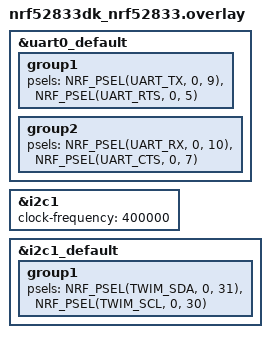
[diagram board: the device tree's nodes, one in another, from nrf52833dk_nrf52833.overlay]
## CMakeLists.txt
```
# SPDX-License-Identifier: Apache-2.0

cmake_minimum_required(VERSION 3.20.0)

find_package(Zephyr REQUIRED HINTS $ENV{ZEPHYR_BASE})
project(NONE)

FILE(GLOB app_sources src/*.c)
# NORDIC SDK APP START
target_sources(app PRIVATE ${app_sources})
# NORDIC SDK APP END
# SPDX-License-Identifier: Apache-2.0
set(FLASH_RUNNER nrfjprog CACHE STRING "" FORCE)
```

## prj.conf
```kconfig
CONFIG_NRFX_TWI0=y
CONFIG_LOG=y


CONFIG_CLOCK_CONTROL_NRF_K32SRC_RC=y
CONFIG_MAIN_STACK_SIZE=1024
CONFIG_NFCT_PINS_AS_GPIOS=y

CONFIG_PM=y
CONFIG_PM_DEVICE=y
CONFIG_PM_DEVICE_RUNTIME=y
```

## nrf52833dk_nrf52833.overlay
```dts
// To get started, press Ctrl+Space to bring up the completion menu and view the available nodes.

// You can also use the buttons in the sidebar to perform actions on nodes.
// Actions currently available include:

// * Enabling / disabling the node
// * Adding the bus to a bus
// * Removing the node
// * Connecting ADC channels

// For more help, browse the DeviceTree documentation at https://docs.zephyrproject.org/latest/guides/dts/index.html
// You can also visit the nRF DeviceTree extension documentation at https://docs.nordicsemi.com/bundle/nrf-connect-vscode/page/guides/ncs_configure_app.html#devicetree-support-in-the-extension

&uart0_default {
	group1 {
		psels = <NRF_PSEL(UART_TX, 0, 9)>, <NRF_PSEL(UART_RTS, 0, 5)>;
	};

	group2 {
		psels = <NRF_PSEL(UART_RX, 0, 10)>, <NRF_PSEL(UART_CTS, 0, 7)>;
	};
};

&i2c1 {
    status = "okay";
    clock-frequency = <400000>;
};

&i2c1_default {
    group1 {
        psels = <NRF_PSEL(TWIM_SDA, 0, 31)>, <NRF_PSEL(TWIM_SCL, 0, 30)>;
    };
};
```

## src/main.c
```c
/*
 * Copyright (c) 2012-2014 Wind River Systems, Inc.
 *
 * SPDX-License-Identifier: Apache-2.0
 */

#include <zephyr/kernel.h>
#include "io.h"
#include "i2c.h"
#include <zephyr/logging/log.h>
#include "ext_io.h"
#include "pinmap.h"
#include "nrfx_power.h"
#include "bat_manage.h"
#include <hal/nrf_power.h>

LOG_MODULE_REGISTER(main, LOG_LEVEL_DBG);

static int regout0_init(void)
{
    /* 若已为 3.3 V 则跳过 */
    if ((NRF_UICR->REGOUT0 & UICR_REGOUT0_VOUT_Msk) ==
         UICR_REGOUT0_VOUT_3V3)
        return 0;

    /* 解锁 NVMC 以写 UICR */
    NRF_NVMC->CONFIG = NVMC_CONFIG_WEN_Wen << NVMC_CONFIG_WEN_Pos;
    while (!NRF_NVMC->READY) { }

    NRF_UICR->REGOUT0 = (NRF_UICR->REGOUT0 &
                         ~UICR_REGOUT0_VOUT_Msk) |
                        UICR_REGOUT0_VOUT_3V3;

    while (!NRF_NVMC->READY) { }
    NRF_NVMC->CONFIG = NVMC_CONFIG_WEN_Ren << NVMC_CONFIG_WEN_Pos;

    /* 强制复位，让新电压生效 */
    NVIC_SystemReset();
    return 0; /* 不会执行到这里 */
}

int i = 0;
int main(void)
{
    regout0_init();

	LOG_DBG("Begin");
	// i2c_init();
	// io_init();

    bat_boost_enable(0);
    current_sample_power_enable(0);

    bat_charger_power_enable(0);
    bat_charger_enable(0);

    ao_en_enable(0);


    while (1)
    {
        // bat_vbat_adc_get();
        // k_msleep(100);
        // statu_led_set(0);
        // k_msleep(1000);
		// i++;
		// LOG_DBG("Hello World! %d", i);
        
        // statu_led_set(1);
        k_msleep(1000);
        
        // nrf_power_system_off(NRF_POWER);
    }

    return 0;
}
```

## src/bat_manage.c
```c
#include <zephyr/kernel.h>
#include "io.h"
#include "i2c.h"
#include <zephyr/logging/log.h>
#include "ext_io.h"
#include "pinmap.h"
#include "nrfx_power.h"
#include "bat_manage.h"


LOG_MODULE_REGISTER(bat, LOG_LEVEL_DBG);


int bat_manage_check(void)
{
    uint8_t val = i2c_read_bytes(BAT_MANAGE_IC_ADDR, BAT_INFO_ADDR);
    if (val == 0x08)
    {
        LOG_DBG("Battery management chip is online");
        return 1;
    }
    else
    {
        LOG_ERR("Battery management chip is offline");
    }
    return 0;
}

int is_bat_online(void)
{
    uint8_t val = i2c_read_bytes(BAT_MANAGE_IC_ADDR, BAT_REG1D_CHARGER_STATUS_2);
    if (val & 0x01)
    {
        LOG_DBG("Battery is online");
        return 1;
    }
    else
    {
        LOG_ERR("Battery is offline");
    }
    return 0;
}

int bat_manage_adc_init(void)
{
    uint8_t val = 0x00;
    i2c_write_bytes(BAT_MANAGE_IC_ADDR, 0x01, val);
    return 0;
}

int bat_adc_status_get(void)
{
    uint8_t val = i2c_read_bytes(BAT_MANAGE_IC_ADDR, BAT_ADC_DISABLE_0);
    LOG_DBG("ADC status 0: %02x", val);
    val = i2c_read_bytes(BAT_MANAGE_IC_ADDR, BAT_ADC_DISABLE_1);
    LOG_DBG("ADC status 1: %02x", val);
    val = i2c_read_bytes(BAT_MANAGE_IC_ADDR, BAT_REG2E_ADC_CONTROL);
    LOG_DBG("ADC control 0x2E: %02x", val);

    i2c_write_bytes(BAT_MANAGE_IC_ADDR, BAT_REG2E_ADC_CONTROL, 0xB0);

    return 0;
}

int bat_current_get(void)
{
    uint8_t val[2] = {0};
    i2c_read_array(BAT_MANAGE_IC_ADDR, BAT_IBAT_ADC, val, 2);
    int16_t current = (val[0] << 8) | val[1];
    LOG_DBG("Battery current: %d", current);
    return current;
}

int bat_charger_status_get(void)
{
    uint8_t val = i2c_read_bytes(BAT_MANAGE_IC_ADDR, BAT_REG1C_CHARGER_STATUS_1);
    LOG_DBG("Charger status: %02x", val);
    return val;
}

int bat_temperature_get(void)
{
    uint8_t val[2] = {0};
    i2c_read_array(BAT_MANAGE_IC_ADDR, BAT_TEMP_ADC, val, 2);
    uint16_t temperature_val = (val[0] << 8) | val[1];
    int temperature = temperature_val  * 0.0976563;
    LOG_DBG("Battery temperature: %d", temperature);
    return temperature;
}

int bat_manage_ic_temp_get(void)
{
    uint8_t val[2] = {0};
    i2c_read_array(BAT_MANAGE_IC_ADDR, BAT_IC_TEMP, val, 2);
    uint16_t temperature_val = (val[0] << 8) | val[1];
    int temperature = -40 + (temperature_val * 0.5);
    LOG_DBG("Battery management chip temperature: %d ", temperature);
    return temperature;
}

int bat_disable_ico(void)
{
    uint8_t val = i2c_read_bytes(BAT_MANAGE_IC_ADDR, BAT_REG0F_CHARGER_CONTROL_0);
    val &= ~((1 << 4) | (1 << 1)); // Clear EN_ICO and FORCE_ICO
    i2c_write_bytes(BAT_MANAGE_IC_ADDR, BAT_REG0F_CHARGER_CONTROL_0, val);
    val = i2c_read_bytes(BAT_MANAGE_IC_ADDR, BAT_REG0F_CHARGER_CONTROL_0);
    LOG_DBG("Charger control register 0x0F: %02x", val);
    return 0;
}


int bat_charger_current_limit_set(uint16_t limit)
{
    uint8_t val[2] = {0};
    if (limit > 5000)
    {
        limit = 5000;
    }

    uint16_t limit_val = limit / 10;
    val[0] = limit_val & 0xFF;
    val[1] = (limit_val >> 8) & 0xFF;

    LOG_DBG("Charger current limit: %02x %02x", val[0], val[1]);

    bat_disable_ico();

    i2c_write_array(BAT_MANAGE_IC_ADDR, BAT_REG03_CURRENT_LIMIT, val, 2);

    uint8_t val_r[2] = {0};
    i2c_read_array(BAT_MANAGE_IC_ADDR, BAT_REG03_CURRENT_LIMIT, val_r, 2);
    uint16_t current_limit = (val_r[0] | (val_r[1] << 8)) * 10;
    LOG_DBG("Charger current limit set to: %d", current_limit);
    return current_limit;

}

int bat_charger_control_set(void)
{
    uint8_t val = i2c_read_bytes(BAT_MANAGE_IC_ADDR, BAT_REG0F_CHARGER_CONTROL_0);
    LOG_DBG("Charger control register: %02x", val);
}

int bat_charger_enable_set(uint8_t enable)
{
    uint8_t val = i2c_read_bytes(BAT_MANAGE_IC_ADDR, BAT_REG0F_CHARGER_CONTROL_0);
    if (enable)
    {
        val |= 0x20;
    }
    else
    {
        val &= ~0x20;
    }
    i2c_write_bytes(BAT_MANAGE_IC_ADDR, BAT_REG0F_CHARGER_CONTROL_0, val);
    return 0;
}

int bat_reg10_charger_control_1_get(void)
{
    uint8_t val = i2c_read_bytes(BAT_MANAGE_IC_ADDR, BAT_REG10_CHARGER_CONTROL_1);
    LOG_DBG("Charger control register 1: %02x", val);
    return val;
}

int bat_reg10_disable_watchdog(void)
{
    uint8_t val = i2c_read_bytes(BAT_MANAGE_IC_ADDR, BAT_REG10_CHARGER_CONTROL_1);
    val &= ~0x07;
    i2c_write_bytes(BAT_MANAGE_IC_ADDR, BAT_REG10_CHARGER_CONTROL_1, val);
    return 0;
}


int bat_input_current_limit_set(uint16_t limit)
{
    uint8_t val[2] = {0};
    if (limit > 3300)
    {
        limit = 3300;
    }

    uint16_t limit_val = (limit - 100) / 10;
    val[0] = limit_val & 0xFF;
    val[1] = (limit_val >> 8) & 0xFF;
    i2c_write_array(BAT_MANAGE_IC_ADDR, BAT_INPUT_CURRENT_LIMIT, val, 2);

    uint8_t val_r[2] = {0};
    i2c_read_array(BAT_MANAGE_IC_ADDR, BAT_INPUT_CURRENT_LIMIT, val_r, 2);
    uint16_t current_limit = (val_r[0] | (val_r[1] << 8)) * 10;
    LOG_DBG("Input current limit set to: %d", current_limit);
    return current_limit;

}

int bat_vbat_adc_get(void)
{
    uint8_t val[2] = {0};
    i2c_read_array(BAT_MANAGE_IC_ADDR, BAT_REG3B_VBAT_ADC, val, 2);
    uint16_t vbat_val = (val[0] << 8) | val[1];
    LOG_DBG("Battery voltage: %d mV", vbat_val);
    return vbat_val;
}
```

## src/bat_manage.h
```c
#ifndef BAT_MANAGE_H
#define BAT_MANAGE_H

#include <zephyr/kernel.h>
#include "io.h"
#include "i2c.h"
#include <zephyr/logging/log.h>
#include "ext_io.h"
#include "pinmap.h"
#include "nrfx_power.h"

#define BAT_MANAGE_IC_ADDR 0x6B
#define BAT_INFO_ADDR 0x48
#define BAT_REG1D_CHARGER_STATUS_2 0x1D
#define BAT_IBAT_ADC 0x33
#define BAT_ADC_DISABLE_0 0x2F
#define BAT_ADC_DISABLE_1 0x30
#define BAT_REG1C_CHARGER_STATUS_1 0x1C
#define BAT_REG2E_ADC_CONTROL 0x2E
#define BAT_IC_TEMP 0x41
#define BAT_TEMP_ADC 0x3F
#define BAT_REG03_CURRENT_LIMIT 0x03
#define BAT_REG0F_CHARGER_CONTROL_0 0x0F
#define BAT_INPUT_CURRENT_LIMIT 0x06
#define BAT_REG10_CHARGER_CONTROL_1 0x10
#define BAT_REG3B_VBAT_ADC 0x3B



int bat_manage_check(void);
int is_bat_online(void);
int bat_manage_adc_init(void);
int bat_adc_status_get(void);
int bat_current_get(void);
int bat_charger_status_get(void);
int bat_temperature_get(void);
int bat_manage_ic_temp_get(void);
int bat_disable_ico(void);
int bat_charger_current_limit_set(uint16_t limit);
int bat_charger_control_set(void);
int bat_charger_enable_set(uint8_t enable);
int bat_reg10_charger_control_1_get(void);
int bat_reg10_disable_watchdog(void);
int bat_input_current_limit_set(uint16_t limit);
int bat_vbat_adc_get(void);

#endif // BAT_MANAGE_H
```

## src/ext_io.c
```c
#include <zephyr/kernel.h>
#include <nrfx_twi.h>
#include <hal/nrf_gpio.h>
#include <zephyr/logging/log.h>
#include "i2c.h"
#include "zephyr/logging/log.h"
#include "ext_io.h"
#include "pinmap.h"


#define EXT_IC_ADDR               0x43  // 7-bit I2C 地址（ADDR 引脚接 GND）

#define REG_DEVICE_ID_CTRL        0x01  // 设备 ID 与控制
#define REG_IO_DIRECTION          0x03  // 引脚方向设置
#define REG_OUTPUT_STATE          0x05  // 输出状态控制
#define REG_PULL_ENABLE           0x0B  // 上拉使能
#define REG_OUTPUT_HIGH_Z         0x07  // 高阻态设置（可选）
#define REG_PULL_DOWN_UP         0x0D  // 上拉/下拉设置（可选）
#define REG_INPUT_STATUS         0x0F  // 输入状态读取

uint8_t ext_io_output_global_val = 0; 


LOG_MODULE_REGISTER(ext_io, LOG_LEVEL_DBG);

void ext_io_sw_reset(void)
{
    uint8_t val = 0x01;
    i2c_write_bytes(EXT_IC_ADDR, REG_DEVICE_ID_CTRL, val);
    k_msleep(10); // 等待 10ms
    val = 0x00;
    i2c_write_bytes(EXT_IC_ADDR, REG_DEVICE_ID_CTRL, val);
    k_msleep(10); // 等待 10ms
    LOG_DBG("External IO reset");
}

uint8_t ext_io_get_io_direction(void)
{
    uint8_t val = i2c_read_bytes(EXT_IC_ADDR, REG_IO_DIRECTION);
    char dir[16] = {0};
    for(uint8_t i = 0; i < 8; i++)
    {
        if(val & (1 << i))
        {
            snprintf(dir + i, 2, "O");  
        }
        else
        {
            snprintf(dir + i, 2, "I");
        }
    }
    LOG_DBG("IO direction: %s", dir);
    return val;
}

void ext_io_set_io_set_all_output(void)
{
    uint8_t val = 0xFF; // 全部设置为输出
    i2c_write_bytes(EXT_IC_ADDR, REG_IO_DIRECTION, val);
    LOG_DBG("Set all IO to output");
}

void ext_io_set_io_set_all_input(void)
{
    uint8_t val = 0x00; // 全部设置为输入
    i2c_write_bytes(EXT_IC_ADDR, REG_IO_DIRECTION, val);
    LOG_DBG("Set all IO to input");
}

void ext_io_set_io_direction(uint8_t io_num, enum ext_io_dir_e dir)
{
    uint8_t val = ext_io_get_io_direction();
    uint8_t new_val = 0;
    
    if(io_num > 7)
    {
        LOG_ERR("Invalid IO number: %d", io_num);
        return;
    }

    if(dir == EXT_IO_DIR_INPUT) // 设置为输入
    {
        val &= ~(1 << io_num);
    }
    else // 设置为输出
    {
        val |= (1 << io_num);
    }
    i2c_write_bytes(EXT_IC_ADDR, REG_IO_DIRECTION, val);
    new_val = ext_io_get_io_direction();

    if(new_val != val)
    {
        LOG_ERR("Failed to set IO direction: %d", io_num);
    }
    else
    {
        LOG_DBG("Set IO %d direction to %s", io_num, dir ? "output" : "input");
    }
}

uint8_t ext_io_get_output_state(void)
{

    return ext_io_output_global_val;

    uint8_t val = i2c_read_bytes(EXT_IC_ADDR, REG_OUTPUT_STATE);
    char state[16] = {0};
    for(uint8_t i = 0; i < 8; i++)
    {
        if(val & (1 << i))
        {
            snprintf(state + i, 2, "H");  

        }
        else
        {
            snprintf(state + i, 2, "L");

        }
    }   
    // LOG_DBG("Output state: %s", state);
    return val;
}

void ext_io_set_output_state(uint8_t io_num, uint8_t state)
{
    uint8_t val = ext_io_get_output_state();
    uint8_t new_val = 0;
    
    if(io_num > 7)
    {
        LOG_ERR("Invalid IO number: %d", io_num);
        return;
    }
    
    if(state) // 设置为高电平
    {
        val |= (1 << io_num);
    }
    else // 设置为低电平
    {
        val &= ~(1 << io_num);
    }
    ext_io_output_global_val = val;
    i2c_write_bytes(EXT_IC_ADDR, REG_OUTPUT_STATE, ext_io_output_global_val);
    new_val = ext_io_get_output_state();

    if(new_val != val)
    {
        LOG_ERR("Failed to set output state: %d", io_num);
    }
    else
    {
        LOG_DBG("Set output %d state to %s", io_num, state ? "high" : "low");
    }
}

uint8_t ext_io_get_output_high_z(void)
{
    uint8_t val = i2c_read_bytes(EXT_IC_ADDR, REG_OUTPUT_HIGH_Z);
    char state[16] = {0};
    for(uint8_t i = 0; i < 8; i++)
    {
        if(val & (1 << i))
        {
            snprintf(state + i, 2, "Z");  
        }
        else
        {
            snprintf(state + i, 2, "P");
        }
    }   
    LOG_DBG("Output high Z: %s", state);
    return val;
}

void ext_io_set_output_high_z(uint8_t io_num, uint8_t state)
{
    uint8_t val = ext_io_get_output_high_z();
    uint8_t new_val = 0;
    
    if(io_num > 7)
    {
        LOG_ERR("Invalid IO number: %d", io_num);
        return;
    }

    if(state) // 设置为高阻态
    {
        val |= (1 << io_num);
    }
    else // 设置为推挽输出
    {
        val &= ~(1 << io_num);
    }
    i2c_write_bytes(EXT_IC_ADDR, REG_OUTPUT_HIGH_Z, val);
    new_val = ext_io_get_output_high_z();

    if(new_val != val)
    {
        LOG_ERR("Failed to set output high Z: %d", io_num);
    }
    else
    {
        LOG_DBG("Set output %d high Z to %s", io_num, state ? "high Z" : "push-pull");
    }
}

uint8_t ext_io_get_pull_enable(void)
{
    uint8_t val = i2c_read_bytes(EXT_IC_ADDR, REG_PULL_ENABLE);
    char state[16] = {0};
    for(uint8_t i = 0; i < 8; i++)
    {
        if(val & (1 << i))
        {
            snprintf(state + i, 2, "P");  
        }
        else
        {
            snprintf(state + i, 2, "N");
        }
    }   
    LOG_DBG("Pull enable: %s", state);
    return val;
}

uint8_t ext_io_get_pull_Down_up(void)
{
    uint8_t val = i2c_read_bytes(EXT_IC_ADDR, REG_PULL_DOWN_UP);
    char state[16] = {0};
    for(uint8_t i = 0; i < 8; i++)
    {
        if(val & (1 << i))
        {
            snprintf(state + i, 2, "U");  
        }
        else
        {
            snprintf(state + i, 2, "D");
        }
    }   
    LOG_DBG("Pull up/down: %s", state);
    return val;
}

uint8_t ext_io_get_input_state(void)
{
    uint8_t val = i2c_read_bytes(EXT_IC_ADDR, REG_INPUT_STATUS);
    char state[16] = {0};
    for(uint8_t i = 0; i < 8; i++)
    {
        if(val & (1 << i))
        {
            snprintf(state + i, 2, "H");  
        }
        else
        {
            snprintf(state + i, 2, "L");
        }
    }   
    LOG_DBG("Input state: %s", state);
    return val;
}

uint8_t ext_io_get_channel_state(uint8_t io_num)
{
    uint8_t val = ext_io_get_input_state();
    
    if(io_num > 7)
    {
        LOG_ERR("Invalid IO number: %d", io_num);
        return 0;
    }

    if(val & (1 << io_num))
    {
        return 1; // 高电平
    }
    else
    {
        return 0; // 低电平
    }
}

uint8_t ext_io_set_pull_enable(uint8_t io_num, uint8_t enable)
{
    uint8_t val = ext_io_get_pull_enable();
    uint8_t new_val = 0;
    
    if(io_num > 7)
    {
        LOG_ERR("Invalid IO number: %d", io_num);
        return 0;
    }

    if(enable) // 设置为使能
    {
        val |= (1 << io_num);
    }
    else // 设置为不使能
    {
        val &= ~(1 << io_num);
    }
    i2c_write_bytes(EXT_IC_ADDR, REG_PULL_ENABLE, val);
    new_val = ext_io_get_pull_enable();

    if(new_val != val)
    {
        LOG_ERR("Failed to set pull enable: %d", io_num);
        return 0;
    }
    else
    {
        LOG_DBG("Set pull enable %d to %s", io_num, enable ? "enable" : "disable");
        return 1;
    }
}

uint8_t ext_io_set_pull_Down_up(uint8_t io_num, uint8_t pull)
{
    uint8_t val = ext_io_get_pull_Down_up();
    uint8_t new_val = 0;
    
    if(io_num > 7)
    {
        LOG_ERR("Invalid IO number: %d", io_num);
        return 0;
    }

    if(pull) // 设置为上拉
    {
        val |= (1 << io_num);
    }
    else // 设置为下拉
    {
        val &= ~(1 << io_num);
    }
    i2c_write_bytes(EXT_IC_ADDR, REG_PULL_DOWN_UP, val);
    new_val = ext_io_get_pull_Down_up();

    if(new_val != val)
    {
        LOG_ERR("Failed to set pull up/down: %d", io_num);
        return 0;
    }
    else
    {
        LOG_DBG("Set pull up/down %d to %s", io_num, pull ? "pull up" : "pull down");
        return 1;
    }
}



void ext_ic_check(void)
{
    uint8_t reg_val = i2c_read_bytes(EXT_IC_ADDR, 0x01);

    uint8_t mf_id     = (reg_val >> 5) & 0x07;  // Bit 7~5
    uint8_t fw_rev    = (reg_val >> 2) & 0x07;  // Bit 4~2
    uint8_t rst_int   = (reg_val >> 1) & 0x01;  // Bit 1
    uint8_t sw_rst    = (reg_val >> 0) & 0x01;  // Bit 0

    LOG_DBG("Manufacturer ID: 0x%X", mf_id);   // 应为 0b101 = 0x5
    LOG_DBG("Firmware Rev:   0x%X", fw_rev);
    LOG_DBG("Reset Flag:     %d", rst_int);
    LOG_DBG("SW Reset Flag:  %d", sw_rst);
}

void statu_led_set(uint8_t status)
{
    if(!status)
    {
        ext_io_set_output_state(LED_EXT_PIN, 1); // 设置为高电平
    }
    else
    {
        ext_io_set_output_state(LED_EXT_PIN, 0); // 设置为低电平
    }
}

uint8_t is_key_on(void)
{
    uint8_t key_state = !ext_io_get_channel_state(KEY_EXT_PIN);
    if(key_state == 1)
    {
        LOG_DBG("Key is pressed");
        return 1;
    }
    else
    {
        LOG_DBG("Key is not pressed");
        return 0;
    }
}

uint8_t is_usb_on(void)
{
    uint8_t usb_state = ext_io_get_channel_state(USB_EXT_PIN);
    if(usb_state == 1)
    {
        LOG_DBG("USB is connected");
        return 1;
    }
    else
    {
        LOG_DBG("USB is not connected");
        return 0;
    }
}


uint8_t ext_io_init(void)
{
    ext_io_sw_reset();

    uint8_t dev_id = i2c_read_bytes(EXT_IC_ADDR, REG_DEVICE_ID_CTRL);

    if (((dev_id >> 5) & 0x07) != 0x05) {
        LOG_ERR("Device not recognized. MF_ID = 0x%X", (dev_id >> 5) & 0x07);
        return false;
    }
    else {
        LOG_DBG("Device recognized. MF_ID = 0x%X", (dev_id >> 5) & 0x07);
    }


    ext_io_set_io_direction(LED_EXT_PIN, EXT_IO_DIR_OUTPUT);
    ext_io_set_io_direction(USB_EXT_PIN, EXT_IO_DIR_INPUT);
    ext_io_set_io_direction(KEY_EXT_PIN, EXT_IO_DIR_INPUT);
    ext_io_set_io_direction(LED_B1_EXT_PIN, EXT_IO_DIR_OUTPUT);
    ext_io_set_io_direction(LED_B2_EXT_PIN, EXT_IO_DIR_OUTPUT);
    ext_io_set_io_direction(LED_B3_EXT_PIN, EXT_IO_DIR_OUTPUT);
    ext_io_set_io_direction(BST_OD_OFF_EXT_PIN, EXT_IO_DIR_OUTPUT);
    ext_io_set_io_direction(PD_OD_OFF_EXT_PIN, EXT_IO_DIR_OUTPUT);

    ext_io_set_pull_enable(LED_EXT_PIN, 0);
    ext_io_set_pull_enable(LED_B1_EXT_PIN, 0);
    ext_io_set_pull_enable(LED_B2_EXT_PIN, 0);
    ext_io_set_pull_enable(LED_B3_EXT_PIN, 0);
    ext_io_set_pull_enable(USB_EXT_PIN, 1);  
    ext_io_set_pull_enable(KEY_EXT_PIN, 1);


    ext_io_set_pull_Down_up(USB_EXT_PIN, 0);    // 设置为下拉
    ext_io_set_pull_Down_up(KEY_EXT_PIN, 1);    // 设置为上拉

    ext_io_set_output_high_z(LED_EXT_PIN, 0); // 设置为推挽输出
    ext_io_set_output_high_z(LED_B1_EXT_PIN, 0); // 设置为推挽输出
    ext_io_set_output_high_z(LED_B2_EXT_PIN, 0); // 设置为推挽输出
    ext_io_set_output_high_z(LED_B3_EXT_PIN, 0); // 设置为推挽输出
    ext_io_set_output_high_z(BST_OD_OFF_EXT_PIN, 0); // 设置为推挽输出
    ext_io_set_output_high_z(PD_OD_OFF_EXT_PIN, 0); // 设置为推挽输出


    ext_io_set_output_state(LED_EXT_PIN, 1); 
    ext_io_set_output_state(LED_B1_EXT_PIN, 1); 
    ext_io_set_output_state(LED_B2_EXT_PIN, 1); 
    ext_io_set_output_state(LED_B3_EXT_PIN, 1);
    ext_io_set_output_state(BST_OD_OFF_EXT_PIN, 0); 
    ext_io_set_output_state(PD_OD_OFF_EXT_PIN, 0); 



    LOG_DBG("External IO initialized finished");

    return true;
}
```

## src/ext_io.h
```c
#ifndef EXT_IO_H
#define EXT_IO_H

#include <stdint.h>



enum ext_io_dir_e{
    EXT_IO_DIR_INPUT = 0,
    EXT_IO_DIR_OUTPUT = 1,
};

// ========== User-defined IO Pin Macros ==========
// Define external IO pin mapping in your project-specific pinmap.h
// Example:
//   #define LED_EXT_PIN            3
//   #define KEY_EXT_PIN            1
//   #define USB_EXT_PIN            2
//   #define LED_B1_EXT_PIN         4
//   #define LED_B2_EXT_PIN         5
//   #define LED_B3_EXT_PIN         6
//   #define BST_OD_OFF_EXT_PIN     7
//   #define PD_OD_OFF_EXT_PIN      0




// ========== Initialization and Status ==========

/**
 * @brief Initialize FXL6408 IO expander
 * @return 1 if successful, 0 if failed
 */
uint8_t ext_io_init(void);

/**
 * @brief Read and log manufacturer ID, firmware version and reset flags
 */
void ext_ic_check(void);


// ========== IO Direction Configuration ==========

/**
 * @brief Read current IO direction register
 * @return 8-bit direction register value
 */
uint8_t ext_io_get_io_direction(void);

/**
 * @brief Set all IOs as output
 */
void ext_io_set_io_set_all_output(void);

/**
 * @brief Set all IOs as input
 */
void ext_io_set_io_set_all_input(void);

/**
 * @brief Set direction for a single IO pin
 * @param io_num IO pin number (0–7)
 * @param dir Direction (input or output)
 */
void ext_io_set_io_direction(uint8_t io_num, enum ext_io_dir_e dir);


// ========== Output Control ==========

/**
 * @brief Read current output state
 * @return 8-bit output register value
 */
uint8_t ext_io_get_output_state(void);

/**
 * @brief Set output value of a single IO pin
 * @param io_num IO pin number (0–7)
 * @param state 1 = High, 0 = Low
 */
void ext_io_set_output_state(uint8_t io_num, uint8_t state);

/**
 * @brief Set output value for multiple pins using mask
 * @param mask Bit mask specifying which pins to modify
 * @param value Desired output values for masked pins
 */
void ext_io_set_output_masked(uint8_t mask, uint8_t value);


// ========== Output Mode: Push-Pull / High-Z ==========

/**
 * @brief Read High-Z state register
 * @return 8-bit value, 1 = High-Z, 0 = Push-pull
 */
uint8_t ext_io_get_output_high_z(void);

/**
 * @brief Configure High-Z or Push-Pull mode for a pin
 * @param io_num IO pin number (0–7)
 * @param state 1 = High-Z (open-drain), 0 = Push-pull
 */
void ext_io_set_output_high_z(uint8_t io_num, uint8_t state);


// ========== Pull-up / Pull-down Configuration ==========

/**
 * @brief Read pull-enable register
 * @return 8-bit value, 1 = Pull enabled, 0 = Disabled
 */
uint8_t ext_io_get_pull_enable(void);

/**
 * @brief Enable or disable internal pull resistor for a pin
 * @param io_num IO pin number (0–7)
 * @param enable 1 = Enable pull, 0 = Disable
 * @return 1 if successful, 0 if failed
 */
uint8_t ext_io_set_pull_enable(uint8_t io_num, uint8_t enable);

/**
 * @brief Read pull-up/down configuration
 * @return 8-bit value, 1 = Pull-up, 0 = Pull-down
 */
uint8_t ext_io_get_pull_Down_up(void);

/**
 * @brief Configure pull direction for a pin
 * @param io_num IO pin number (0–7)
 * @param pull 1 = Pull-up, 0 = Pull-down
 * @return 1 if successful, 0 if failed
 */
uint8_t ext_io_set_pull_Down_up(uint8_t io_num, uint8_t pull);


// ========== Input State ==========

/**
 * @brief Read all input states
 * @return 8-bit input level of all pins
 */
uint8_t ext_io_get_input_state(void);

/**
 * @brief Read input state of a single IO pin
 * @param io_num IO pin number (0–7)
 * @return 1 = High, 0 = Low
 */
uint8_t ext_io_get_channel_state(uint8_t io_num);


// ========== Application-level API ==========

/**
 * @brief Set status LED on or off
 * @param status 1 = On, 0 = Off
 */
void statu_led_set(uint8_t status);

/**
 * @brief Check if key input is active (pressed)
 * @return 1 = Pressed, 0 = Not pressed
 */
uint8_t is_key_on(void);

/**
 * @brief Check if USB is connected
 * @return 1 = Connected, 0 = Not connected
 */
uint8_t is_usb_on(void);


#endif // EXT_IO_H
```

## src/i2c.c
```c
#include <zephyr/kernel.h>
#include <nrfx_twi.h>
#include <hal/nrf_gpio.h>
#include <zephyr/logging/log.h>
#include "pinmap.h"
#include "i2c_zephyr.h"

LOG_MODULE_REGISTER(iic, LOG_LEVEL_DBG);

static const nrfx_twi_t twi = NRFX_TWI_INSTANCE(0);

void twi_handler(nrfx_twi_evt_t const * p_event, void * p_context) 
{
	switch (p_event->type) {
		case NRFX_TWI_EVT_DONE:
			/* Transfer completed */
			break;
		case NRFX_TWI_EVT_ADDRESS_NACK:
			/* NACK received after sending the address */
			break;
		case NRFX_TWI_EVT_DATA_NACK:
			/* NACK received after sending a data byte */
			break;
		default:
			break;
	}
}

void i2c_init(void)
{
	int err_code;
    nrfx_twi_config_t config = NRFX_TWI_DEFAULT_CONFIG(I2C_SCL_PIN, I2C_SDA_PIN);
	config.frequency = NRF_TWI_FREQ_400K;
    err_code = nrfx_twi_init(&twi, &config, twi_handler, NULL);
	if (err_code != NRFX_SUCCESS) {
		LOG_ERR("TWI initialization failed: %d", err_code);
		return;
	}
    IRQ_DIRECT_CONNECT(NRFX_IRQ_NUMBER_GET(NRF_TWI_INST_GET(0)), IRQ_PRIO_LOWEST,
                       NRFX_TWI_INST_HANDLER_GET(0), 0);
    nrfx_twi_enable(&twi);
}
uint8_t buffer[2] = {0};
uint8_t i2c_write_bytes(uint8_t ic_addr, uint8_t addr, uint8_t data) 
{
	z_i2c_write(ic_addr, addr, &data, 1);
	return 0;

	buffer[0] = addr;
	buffer[1] = data;
	nrfx_twi_xfer_desc_t xfer_desc = {
		.type = NRFX_TWI_XFER_TX,
		.address = ic_addr,
		.primary_length = sizeof(buffer),
		.p_primary_buf = buffer,
	};

	while(nrfx_twi_is_busy(&twi)){};
	nrfx_twi_xfer(&twi, &xfer_desc, 0);
	return 0;
}

uint8_t i2c_write_array(uint8_t ic_addr, uint8_t addr, uint8_t *data, uint8_t len) 
{
	uint8_t buffer[len + 1];
	buffer[0] = addr;
	for (int i = 0; i < len; i++) {
		buffer[i + 1] = data[i];
	}
	nrfx_twi_xfer_desc_t xfer_desc = {
		.type = NRFX_TWI_XFER_TXTX,
		.address = ic_addr,
		.primary_length = sizeof(buffer),
		.p_primary_buf = buffer,
	};

	while(nrfx_twi_is_busy(&twi)){};
	nrfx_twi_xfer(&twi, &xfer_desc, 0);
	return 0;
}


uint8_t i2c_read_bytes(uint8_t ic_addr, uint8_t addr) 
{
	uint8_t addr_buffer[1] = {addr};
	uint8_t data_buffer[1];

	z_i2c_read(ic_addr, addr, data_buffer, 1);
	return data_buffer[0];

	nrfx_twi_xfer_desc_t xfer_desc = {
		.type = NRFX_TWI_XFER_TXRX,
		.address = ic_addr,
		.primary_length = sizeof(addr_buffer),
		.p_primary_buf = addr_buffer,
		.secondary_length = sizeof(data_buffer),
		.p_secondary_buf = data_buffer,
	};

	
	nrfx_twi_xfer(&twi, &xfer_desc, 0);
	while(nrfx_twi_is_busy(&twi)){};
	return data_buffer[0];
}

uint8_t i2c_read_data_buffer[20] = {0};
uint8_t i2c_read_array(uint8_t ic_addr, uint8_t addr, uint8_t *data, uint8_t len) 
{
	uint8_t addr_buffer[1] = {addr};
	for (int i = 0; i < len; i++) {
		i2c_read_data_buffer[i] = 0;
	}

	nrfx_twi_xfer_desc_t xfer_desc = {
		.type = NRFX_TWI_XFER_TXRX,
		.address = ic_addr,
		.primary_length = sizeof(addr_buffer),
		.p_primary_buf = addr_buffer,
		.secondary_length = len,
		.p_secondary_buf = i2c_read_data_buffer,
	};

	
	nrfx_twi_xfer(&twi, &xfer_desc, 0);
	while(nrfx_twi_is_busy(&twi)){};
	for (int i = 0; i < len; i++) {
		data[i] = i2c_read_data_buffer[i];
	}
	return 0;
}
```

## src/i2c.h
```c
#ifndef I2C_H
#define I2C_H

#include <stdint.h>

void i2c_init(void);
uint8_t i2c_write_bytes(uint8_t ic_addr, uint8_t addr, uint8_t data);
uint8_t i2c_write_array(uint8_t ic_addr, uint8_t addr, uint8_t *data, uint8_t len);
uint8_t i2c_read_bytes(uint8_t ic_addr, uint8_t addr);
uint8_t i2c_read_array(uint8_t ic_addr, uint8_t addr, uint8_t *data, uint8_t len);

#endif // I2C_H
```

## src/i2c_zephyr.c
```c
#include <zephyr/kernel.h>
#include <zephyr/device.h>
#include <zephyr/devicetree.h>
#include <zephyr/logging/log.h>
#include <zephyr/drivers/i2c.h>


LOG_MODULE_REGISTER(i2c_zephyr, LOG_LEVEL_DBG);
const struct device *i2c_dev = DEVICE_DT_GET(DT_NODELABEL(i2c1));

void z_i2c_write(uint8_t ic_addr, uint8_t addr, uint8_t *data, uint8_t len)
{
	struct i2c_msg msgs[2];
	msgs[0].buf = &addr;
	msgs[0].len = 1;
	msgs[0].flags = I2C_MSG_WRITE;
	msgs[1].buf = data;
	msgs[1].len = len;
	msgs[1].flags = I2C_MSG_WRITE | I2C_MSG_STOP;

	i2c_transfer(i2c_dev, msgs, 2, ic_addr);
}

void z_i2c_read(uint8_t ic_addr, uint8_t addr, uint8_t *data, uint8_t len)
{
	struct i2c_msg msgs[2];
	msgs[0].buf = &addr;
	msgs[0].len = 1;
	msgs[0].flags = I2C_MSG_WRITE | I2C_MSG_STOP;
	msgs[1].buf = data;
	msgs[1].len = len;
	msgs[1].flags = I2C_MSG_READ | I2C_MSG_STOP;

	i2c_transfer(i2c_dev, msgs, 2, ic_addr);
}

void z_i2c_init(void)
{
	if(!device_is_ready(i2c_dev)){
		LOG_ERR("I2C device is not ready");
		return -1;
	}
	else{
		LOG_INF("I2C device is ready");
	}
}
```

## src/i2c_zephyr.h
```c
#ifndef I2C_ZEPHYR_H
#define I2C_ZEPHYR_H

#include <stdint.h>
#include <zephyr/drivers/i2c.h>

void z_i2c_write(uint8_t ic_addr, uint8_t addr, uint8_t *data, uint8_t len);
void z_i2c_read(uint8_t ic_addr, uint8_t addr, uint8_t *data, uint8_t len);
void z_i2c_init(void);

#endif // I2C_ZEPHYR_H
```

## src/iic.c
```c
#include <zephyr/kernel.h>
#include <nrfx_twi.h>
#include <hal/nrf_gpio.h>
#include <zephyr/logging/log.h>
#include "pinmap.h"

LOG_MODULE_REGISTER(iic, LOG_LEVEL_INF);

static const nrfx_twi_t twi = NRFX_TWI_INSTANCE(0);

void twi_handler(nrfx_twi_evt_t const * p_event, void * p_context) 
{
	switch (p_event->type) {
		case NRFX_TWI_EVT_DONE:
			/* Transfer completed */
			break;
		case NRFX_TWI_EVT_ADDRESS_NACK:
			/* NACK received after sending the address */
			break;
		case NRFX_TWI_EVT_DATA_NACK:
			/* NACK received after sending a data byte */
			break;
		default:
			break;
	}
}

void i2c_init(void)
{
    nrfx_twi_config_t config = NRFX_TWI_DEFAULT_CONFIG(I2C_SCL_PIN, I2C_SDA_PIN);
    nrfx_twi_init(&twi, &config, twi_handler, NULL);
    IRQ_DIRECT_CONNECT(NRFX_IRQ_NUMBER_GET(NRF_TWI_INST_GET(0)), IRQ_PRIO_LOWEST,
                       NRFX_TWI_INST_HANDLER_GET(0), 0);
    nrfx_twi_enable(&twi);
}
```

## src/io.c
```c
#include "pinmap.h"
#include <zephyr/kernel.h>
#include <hal/nrf_gpio.h>

#include <zephyr/logging/log.h>

#include "io.h"
#include "ext_io.h"

#include "bat_manage.h"

LOG_MODULE_REGISTER(io, LOG_LEVEL_INF);

void io_config_high_drive(uint32_t pin_number)
{
    nrf_gpio_cfg(
        pin_number,
        NRF_GPIO_PIN_DIR_OUTPUT,
        NRF_GPIO_PIN_INPUT_DISCONNECT,
        NRF_GPIO_PIN_NOPULL,
        NRF_GPIO_PIN_S0H1,
        NRF_GPIO_PIN_NOSENSE);
}

void io_init(void)
{
    nrf_gpio_cfg_output(BQ25792_BAT_CE_PIN);
    nrf_gpio_cfg_output(CHARGE_ENABLE_PIN);
    nrf_gpio_cfg_output(BAT_CHARGER_POWER_PIN);
    nrf_gpio_cfg_output(VOUT_5V_POWER_PIN);
    nrf_gpio_cfg_output(AO_EN_PIN);

    nrf_gpio_cfg_output(VS_IN_PIN);

    io_config_high_drive(VLED_CUR_TRI1_PIN);
    io_config_high_drive(VLED_CUR_TRI2_PIN);
    io_config_high_drive(VLED_CUR_TRI3_PIN);
    io_config_high_drive(VLED_CUR_TRI4_PIN);
    io_config_high_drive(VLED_CUR_TRI5_PIN);
    io_config_high_drive(VLED_CUR_TRI6_PIN);

    io_config_high_drive(FAN_PIN);
    nrf_gpio_pin_clear(FAN_PIN);


    nrf_gpio_pin_clear(VLED_CUR_TRI5_PIN);
    nrf_gpio_pin_clear(VLED_CUR_TRI6_PIN);

    nrf_gpio_pin_set(VS_IN_PIN);

    uint8_t ret = ext_io_init();
    if (ret) {
        LOG_INF("External IO initialized successfully");
    } else {
        LOG_ERR("External IO initialization failed");
    }

}   

void io_test(void)
{
    bat_charger_enable(1);
    bat_boost_enable(1);
    bat_charger_power_enable(1);
    vout_5v_power_enable(1);
    ao_en_enable(1);
    current_sample_power_enable(1);
    k_msleep(1000);

    bat_charger_enable(0);
    bat_boost_enable(0);
    bat_charger_power_enable(0);
    vout_5v_power_enable(0);
    ao_en_enable(0);
    current_sample_power_enable(0);
    k_msleep(1000);
}

void bat_charger_enable(uint8_t enable)
{
    if (enable) {
        nrf_gpio_pin_clear(BQ25792_BAT_CE_PIN);
        bat_charger_enable_set(1);
    } else {
        nrf_gpio_pin_set(BQ25792_BAT_CE_PIN);
        bat_charger_enable_set(0);
    }
}

void bat_boost_enable(uint8_t enable)
{
    if (enable) {
        nrf_gpio_pin_set(CHARGE_ENABLE_PIN);
    } else {
        nrf_gpio_pin_clear(CHARGE_ENABLE_PIN);
    }
}

void bat_charger_power_enable(uint8_t enable)
{
    if (enable) {
        nrf_gpio_pin_set(BAT_CHARGER_POWER_PIN);
    } else {
        nrf_gpio_pin_clear(BAT_CHARGER_POWER_PIN);
    }
}

void vout_5v_power_enable(uint8_t enable)
{
    if (enable) {
        nrf_gpio_pin_set(VOUT_5V_POWER_PIN);
    } else {
        nrf_gpio_pin_clear(VOUT_5V_POWER_PIN);
    }
}

void ao_en_enable(uint8_t enable)
{
    if (enable) {
        nrf_gpio_pin_set(AO_EN_PIN);
    } else {
        nrf_gpio_pin_clear(AO_EN_PIN);
    }
}

void current_sample_power_enable(uint8_t enable)
{
    if (enable) {
        nrf_gpio_pin_clear(VS_IN_PIN);
    } else {
        nrf_gpio_pin_set(VS_IN_PIN);
    }
}
```

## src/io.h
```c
#ifndef IO_H
#define IO_H

void io_init(void);
void io_test(void);
void bat_charger_enable(uint8_t enable);
void bat_boost_enable(uint8_t enable);
void bat_charger_power_enable(uint8_t enable);
void vout_5v_power_enable(uint8_t enable);
void ao_en_enable(uint8_t enable);
void current_sample_power_enable(uint8_t enable);


#endif // IO_H
```

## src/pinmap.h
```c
#ifndef PINMAP_H
#define PINMAP_H

#include <hal/nrf_gpio.h>
#include <zephyr/kernel.h>  

// PIN MAP
// AO_NTC -> P0.01     // AO Power channel ntc analog input
// FAN -> P0.00        // FAN PWM output


// UART0_TX -> P0.09   
// UART0_RX -> P0.10

// BQ25792_BAT_CE -> P0.05     // BQ25792 Battery charger chip enable

// I2C_SCL -> P1.09
// I2C_SDA -> P0.11

// CHARGE_ENABLE -> P0.15      // Enable bat boost channel

// LO_EN2 -> P0.17     // Enable bat charger power
// LO_EN1 -> P0.18     // Enable 5V output power
// AO_EN -> P0.04      // Enable adjustable power output

// VLED_CUR_TRI1 -> P0.02      // Trigger current sample channel 1
// VLED_CUR_TRI2 -> P0.03      // Trigger current sample channel 2
// VLED_CUR_TRI3 -> P0.28    // Trigger current sample channel 3
// VLED_CUR_TRI4 -> P0.29      // Trigger current sample channel 4
// VLED_CUR_TRI5 -> P0.30    // Trigger current sample channel 5
// VLED_CUR_TRI6 -> P0.31  // Trigger current sample channel 6

// VS_IN -> P0.20         // Enable current sample circuit power

// LED -> PE -> 7          // Function LED
// USB_DET -> PE -> 6      // PD USB detection
// KEY -> PE -> 5          // Key input
// LED_B1 -> PE -> 4       // Soc LED 1
// LED_B2 -> PE -> 3       // Soc LED 2
// LED_B3 -> PE -> 2       // Soc LED 3
// BST_OD_OFF -> PE -> 0   // Bat boost output diode off
// PD_OD_OFF -> PE -> 1    // PD output diode off

#define LED_EXT_PIN     7
#define USB_EXT_PIN    6
#define KEY_EXT_PIN     5
#define LED_B1_EXT_PIN  4
#define LED_B2_EXT_PIN  3
#define LED_B3_EXT_PIN  2
#define BST_OD_OFF_EXT_PIN 0
#define PD_OD_OFF_EXT_PIN 1

// Pin definitions
#define FAN_PIN NRF_GPIO_PIN_MAP(0, 0)
#define UART0_TX_PIN NRF_GPIO_PIN_MAP(0, 9)
#define UART0_RX_PIN NRF_GPIO_PIN_MAP(0, 10)
#define AO_NTC_PIN NRF_GPIO_PIN_MAP(0, 1)
#define BQ25792_BAT_CE_PIN NRF_GPIO_PIN_MAP(0, 5)
#define I2C_SCL_PIN NRF_GPIO_PIN_MAP(1, 9)
#define I2C_SDA_PIN NRF_GPIO_PIN_MAP(0, 11)
#define CHARGE_ENABLE_PIN NRF_GPIO_PIN_MAP(0, 15)
#define LO_EN2_PIN NRF_GPIO_PIN_MAP(0, 17)
#define LO_EN1_PIN NRF_GPIO_PIN_MAP(0, 18)
#define AO_EN_PIN NRF_GPIO_PIN_MAP(0, 4)
#define VLED_CUR_TRI1_PIN NRF_GPIO_PIN_MAP(0, 2)
#define VLED_CUR_TRI2_PIN NRF_GPIO_PIN_MAP(0, 3)
#define VLED_CUR_TRI3_PIN NRF_GPIO_PIN_MAP(0, 28)
#define VLED_CUR_TRI4_PIN NRF_GPIO_PIN_MAP(0, 29)
#define VLED_CUR_TRI5_PIN NRF_GPIO_PIN_MAP(0, 30)
#define VLED_CUR_TRI6_PIN NRF_GPIO_PIN_MAP(0, 31)
#define VS_IN_PIN NRF_GPIO_PIN_MAP(0, 20)

#define BAT_CHARGER_POWER_PIN LO_EN2_PIN
#define VOUT_5V_POWER_PIN LO_EN1_PIN

#endif // PINMAP_H
```
